# f28002x_xbar_regs register map
Vendor: Texas Instruments
Peripheral module from a debugger description file (folder C2000).
Address unit: 16 bits
Registers are 32-bit, read-only, no defined reset value unless marked. A register's access mark holds for its fields unless they carry their own. Offsets are as the file gives them; lines under a group give offsets from that group; [hi:lo] are bit positions; {n}, {i} and the like mark numbered series; 'fields as' and 'values as' point back to an identical list; <NAME> marks a mode.

## XBAR_REGS — XBAR Registers
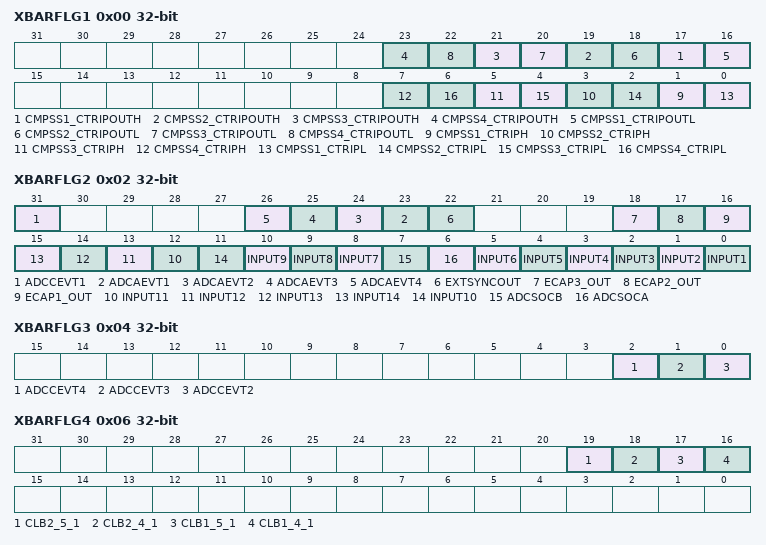
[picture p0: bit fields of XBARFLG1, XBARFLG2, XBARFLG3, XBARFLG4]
0x00 XBARFLG1 — X-Bar Input Flag Register 1
  [2n+15] CMPSS{n}_CTRIPOUTH (n=1..4) — Input Flag for CMPSS{n}.CTRIPOUTH Signal
  [2n+14] CMPSS{n}_CTRIPOUTL (n=1..4) — Input Flag for CMPSS{n}.CTRIPOUTL Signal
  [2n-1] CMPSS{n}_CTRIPH (n=1..4) — Input Flag for CMPSS{n}.CTRIPH Signal
  [2n-2] CMPSS{n}_CTRIPL (n=1..4) — Input Flag for CMPSS{n}.CTRIPL Signal
0x02 XBARFLG2 — X-Bar Input Flag Register 2
  [31] ADCCEVT1 — Input Flag for ADCCEVT1 Signal
  [n+22] ADCAEVT{n} (n=1..4) — Input Flag for ADCAEVT{n} Signal
  [22] EXTSYNCOUT — Input Flag for EXTSYNCOUT Signal
  [18] ECAP3_OUT — Input Flag for ECAP3.OUT Signal
  [17] ECAP2_OUT — Input Flag for ECAP2.OUT Signal
  [16] ECAP1_OUT — Input Flag for ECAP1.OUT Signal
  [n+1] INPUT{n} (n=11..14) — Input Flag for INPUT{n} Signal
  [11] INPUT10 — Input Flag for INPUT10\ Signal
  [10] INPUT9 — Input Flag for INPUT9 Signal
  [9] INPUT8 — Input Flag for INPUT8 Signal
  [8] INPUT7 — Input Flag for INPUT7 Signal
  [7] ADCSOCB — Input Flag for ADCSOCB Signal
  [6] ADCSOCA — Input Flag for ADCSOCA Signal
  [n-1] INPUT{n} (n=1..6) — Input Flag for INPUT{n} Signal
0x04 XBARFLG3 — X-Bar Input Flag Register 3
  [2] ADCCEVT4 — Input Flag for ADCCEVT4 Signal
  [1] ADCCEVT3 — Input Flag for ADCCEVT3 Signal
  [0] ADCCEVT2 — Input Flag for ADCCEVT2 Signal
0x06 XBARFLG4 — X-Bar Input Flag Register 4
  [19] CLB2_5_1 — Input Flag for CLB2_5.1 Signal
  [18] CLB2_4_1 — Input Flag for CLB2_4.1 Signal
  [17] CLB1_5_1 — Input Flag for CLB1_5.1 Signal
  [16] CLB1_4_1 — Input Flag for CLB1_4.1 Signal
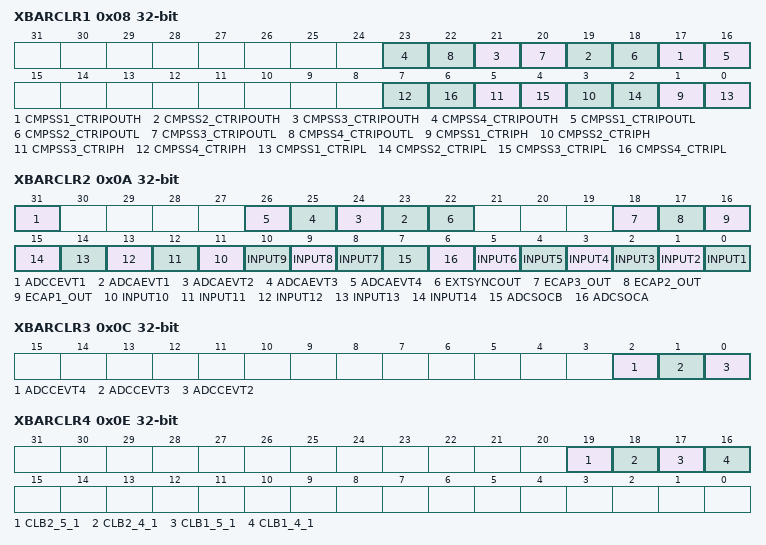
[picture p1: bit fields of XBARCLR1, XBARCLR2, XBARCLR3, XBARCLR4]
0x08 XBARCLR1 rw — X-Bar Input Flag Clear Register 1
  [2n+15] CMPSS{n}_CTRIPOUTH (n=1..4) — Input Flag Clear for CMPSS{n}.CTRIPOUTH Signal
  [2n+14] CMPSS{n}_CTRIPOUTL (n=1..4) — Input Flag Clear for CMPSS{n}.CTRIPOUTL Signal
  [2n-1] CMPSS{n}_CTRIPH (n=1..4) — Input Flag Clear for CMPSS{n}.CTRIPH Signal
  [2n-2] CMPSS{n}_CTRIPL (n=1..4) — Input Flag Clear for CMPSS{n}.CTRIPL Signal
0x0A XBARCLR2 rw — X-Bar Input Flag Clear Register 2
  [31] ADCCEVT1 — Input Flag Clear for ADCCEVT1 Signal
  [n+22] ADCAEVT{n} (n=1..4) — Input Flag Clear for ADCAEVT{n} Signal
  [22] EXTSYNCOUT — Input Flag Clear for EXTSYNCOUT Signal
  [18] ECAP3_OUT — Input Flag Clear for ECAP3.OUT Signal
  [17] ECAP2_OUT — Input Flag Clear for ECAP2.OUT Signal
  [16] ECAP1_OUT — Input Flag Clear for ECAP1.OUT Signal
  [n+1] INPUT{n} (n=7..14) — Input Flag Clear for INPUT{n} Signal
  [7] ADCSOCB — Input Flag Clear for ADCSOCB Signal
  [6] ADCSOCA — Input Flag Clear for ADCSOCA Signal
  [n-1] INPUT{n} (n=1..6) — Input Flag Clear for INPUT{n} Signal
0x0C XBARCLR3 rw — X-Bar Input Flag Clear Register 3
  [2] ADCCEVT4 — Input Flag Clear for ADCCEVT4 Signal
  [1] ADCCEVT3 — Input Flag Clear for ADCCEVT3 Signal
  [0] ADCCEVT2 — Input Flag Clear for ADCCEVT2 Signal
0x0E XBARCLR4 — X-Bar Input Flag Clear Register 4
  [19] CLB2_5_1 — Input Flag clear for CLB2_5.1 Signal
  [18] CLB2_4_1 — Input Flag clear for CLB2_4.1 Signal
  [17] CLB1_5_1 — Input Flag clear for CLB1_5.1 Signal
  [16] CLB1_4_1 — Input Flag clear for CLB1_4.1 Signal
